VERSION ""

NS_ :

BS_:

BU_: Javed Woof

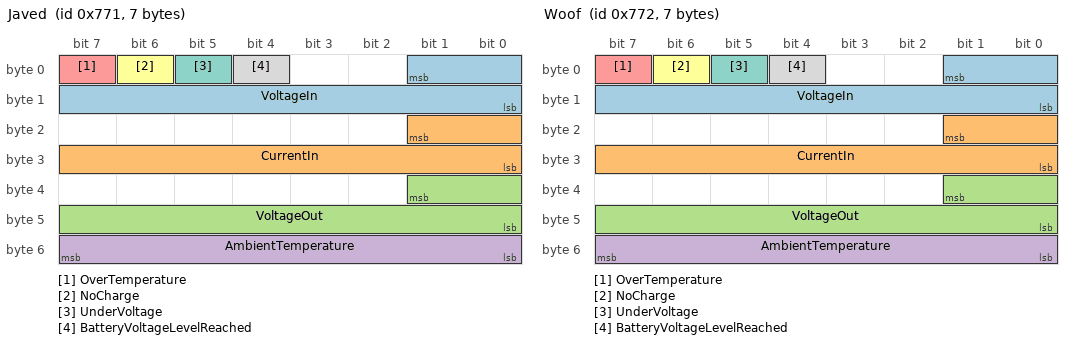
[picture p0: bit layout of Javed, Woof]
BO_ 1905 Javed: 7 Vector__XXX
 SG_ VoltageIn : 1|10@0+ (1,0) [0|0] "" Vector__XXX
 SG_ CurrentIn : 17|10@0+ (1,0) [0|0] "" Vector__XXX
 SG_ VoltageOut : 33|10@0+ (1,0) [0|0] "" Vector__XXX
 SG_ AmbientTemperature : 55|8@0+ (1,0) [0|0] "" Vector__XXX
 SG_ OverTemperature : 7|1@0+ (1,0) [0|0] "" Vector__XXX
 SG_ NoCharge : 6|1@0+ (1,0) [0|0] "" Vector__XXX
 SG_ UnderVoltage : 5|1@0+ (1,0) [0|0] "" Vector__XXX
 SG_ BatteryVoltageLevelReached : 4|1@0+ (1,0) [0|0] "" Vector__XXX

BO_ 1906 Woof: 7 Vector__XXX
 SG_ VoltageIn : 1|10@0+ (1,0) [0|0] "" Vector__XXX
 SG_ CurrentIn : 17|10@0+ (1,0) [0|0] "" Vector__XXX
 SG_ VoltageOut : 33|10@0+ (1,0) [0|0] "" Vector__XXX
 SG_ AmbientTemperature : 55|8@0+ (1,0) [0|0] "" Vector__XXX
 SG_ OverTemperature : 7|1@0+ (1,0) [0|0] "" Vector__XXX
 SG_ NoCharge : 6|1@0+ (1,0) [0|0] "" Vector__XXX
 SG_ UnderVoltage : 5|1@0+ (1,0) [0|0] "" Vector__XXX
 SG_ BatteryVoltageLevelReached : 4|1@0+ (1,0) [0|0] "" Vector__XXX

BO_ 1809 MPPT_poll_javed: 1 Vector__XXX
 SG_ Blank : 0|8@1- (1,0) [0|0] "" Vector__XXX

BO_ 1810 MPPT_poll_woof: 1 Vector__XXX
 SG_ Blank : 0|8@1- (1,0) [0|0] "" Vector__XXX
